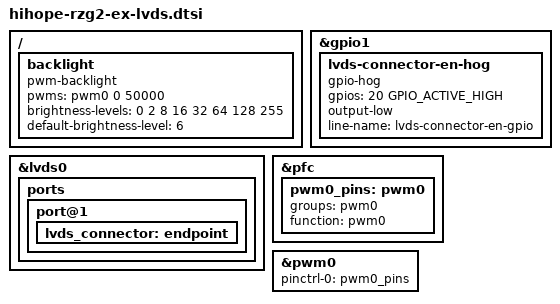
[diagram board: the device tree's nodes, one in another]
/ {
	backlight {
		compatible = "pwm-backlight";
		pwms = <&pwm0 0 50000>;
		brightness-levels = <0 2 8 16 32 64 128 255>;
		default-brightness-level = <6>;
	};
};
&gpio1 {
	lvds-connector-en-hog {
		gpio-hog;
		gpios = <20 GPIO_ACTIVE_HIGH>;
		output-low;
		line-name = "lvds-connector-en-gpio";
	};
};
&lvds0 {
	ports {
		port@1 {
			lvds_connector: endpoint {
			};
		};
	};
};
&pfc {
	pwm0_pins: pwm0 {
		groups = "pwm0";
		function = "pwm0";
	};
};
&pwm0 {
	pinctrl-0 = <&pwm0_pins>;
	pinctrl-names = "default";
	status = "okay";
};
